# pwrseq_me30 register map
Registers are access not given, no defined reset value unless marked. A register's access mark holds for its fields unless they carry their own. Offsets are from the block's base; lines under a group give offsets from that group; [hi:lo] are bit positions; {n}, {i} and the like mark numbered series; 'fields as' and 'values as' point back to an identical list; <NAME> marks a mode.

## Memory map
0x40006800 PWRSEQ size 0x400 — Power Sequencer / Low Power Control Register.

## PWRSEQ — Power Sequencer / Low Power Control Register.
Base 0x40006800
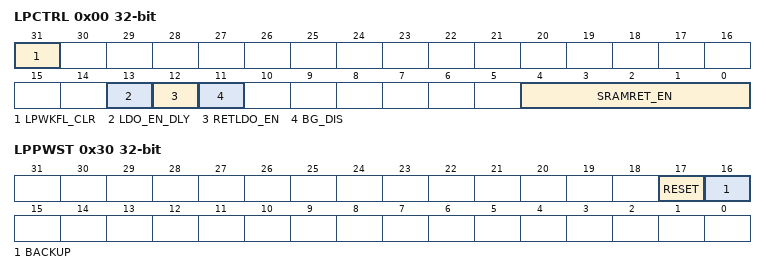
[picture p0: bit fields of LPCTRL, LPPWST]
0x00 LPCTRL — Low Power Control Register.
  [31] LPWKFL_CLR wo write-1-clears — LP wakeup flag register clear. Write 1 to clear all wakeup flags in LPWKFL0.
  [13] LDO_EN_DLY — Core LDO Enable Delay.
    0=dis (Disable.); 1=en (Enable delay LDO power up to smooth LDO voltage drop.)
  [12] RETLDO_EN — Retention LDO Enable.
    0=dis (Disable.); 1=en (Enable.)
  [11] BG_DIS — Bandgap OFF. This controls the System Bandgap in DeepSleep mode.
    0=on (Bandgap is always ON.); 1=off (Bandgap is OFF in DeepSleep mode (default).)
  [4:0] SRAMRET_EN — System RAM retention in BACKUP mode. These bits select which SRAM blocks are retained in BACKUP mode.
0x04 LPWKFL0 — Low Power I/O Wakeup Status Register 0. This register indicates the low power wakeup status for GPIO0.
  [13:0] PINS write-1-clears — Wakeup Flags for GPIO0 pins [13:0]. Each bit corresponds to one GPIO0 pin. Write 1 to clear.
0x08 LPWKEN0 — Low Power I/O Wakeup Enable Register 0. This register enables low power wakeup functionality for GPIO0.
  [13:0] PINS — Enable wakeup for GPIO0 pins [13:0]. Each bit allows wakeup from the corresponding GPIO0 pin on a low-to-high or high-to-low transition when PM.GPIOWKEN is set. Wakeup status is indicated in LPWKFL0.
0x30 LPPWST — Low Power Peripheral Wakeup Status Register.
  [17] RESET write-1-clears — Reset Detected Wakeup Flag. Write 1 to clear.
  [16] BACKUP write-1-clears — BACKUP Wakeful Flag. Write 1 to clear.
0x48 GP0 — General Purpose Register 0
0x4C GP1 — General Purpose Register 1
